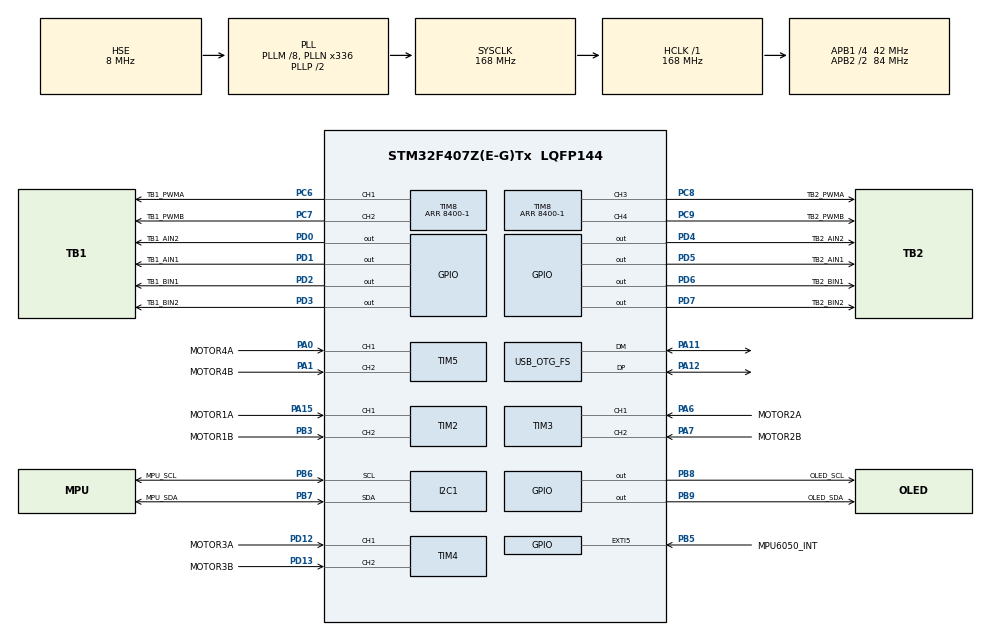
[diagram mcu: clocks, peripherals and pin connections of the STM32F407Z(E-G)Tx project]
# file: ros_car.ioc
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Dma.I2C1_RX.0.Direction=DMA_PERIPH_TO_MEMORY
Dma.I2C1_RX.0.FIFOMode=DMA_FIFOMODE_DISABLE
Dma.I2C1_RX.0.Instance=DMA1_Stream0
Dma.I2C1_RX.0.MemDataAlignment=DMA_MDATAALIGN_BYTE
Dma.I2C1_RX.0.MemInc=DMA_MINC_ENABLE
Dma.I2C1_RX.0.Mode=DMA_NORMAL
Dma.I2C1_RX.0.PeriphDataAlignment=DMA_PDATAALIGN_BYTE
Dma.I2C1_RX.0.PeriphInc=DMA_PINC_DISABLE
Dma.I2C1_RX.0.Priority=DMA_PRIORITY_HIGH
Dma.I2C1_TX.1.Direction=DMA_MEMORY_TO_PERIPH
Dma.I2C1_TX.1.FIFOMode=DMA_FIFOMODE_DISABLE
Dma.I2C1_TX.1.Instance=DMA1_Stream6
Dma.I2C1_TX.1.MemDataAlignment=DMA_MDATAALIGN_BYTE
Dma.I2C1_TX.1.MemInc=DMA_MINC_ENABLE
Dma.I2C1_TX.1.Mode=DMA_NORMAL
Dma.I2C1_TX.1.PeriphDataAlignment=DMA_PDATAALIGN_BYTE
Dma.I2C1_TX.1.PeriphInc=DMA_PINC_DISABLE
Dma.I2C1_TX.1.Priority=DMA_PRIORITY_HIGH
Dma.Request0=I2C1_RX
Dma.Request1=I2C1_TX
FREERTOS.Tasks01=defaultTask,24,128,StartDefaultTask,Default,NULL,Dynamic,NULL,NULL
Mcu.Family=STM32F4
Mcu.Name=STM32F407Z(E-G)Tx
Mcu.Package=LQFP144
NVIC.DMA1_Stream0_IRQn=true\:5\:0\:false\:false\:true\:true\:false\:true\:true
NVIC.DMA1_Stream6_IRQn=true\:5\:0\:false\:false\:true\:true\:false\:true\:true
NVIC.EXTI9_5_IRQn=true\:5\:0\:false\:false\:true\:true\:true\:true\:true
NVIC.I2C1_ER_IRQn=true\:5\:0\:false\:false\:true\:true\:true\:true\:true
NVIC.I2C1_EV_IRQn=true\:5\:0\:false\:false\:true\:true\:true\:true\:true
NVIC.OTG_FS_IRQn=true\:5\:0\:false\:false\:true\:true\:false\:true\:true
NVIC.PriorityGroup=NVIC_PRIORITYGROUP_4
NVIC.TIM1_UP_TIM10_IRQn=true\:15\:0\:false\:false\:true\:false\:false\:true\:true
NVIC.TIM8_TRG_COM_TIM14_IRQn=true\:5\:0\:false\:false\:true\:false\:false\:true\:true
NVIC.TimeBase=TIM1_UP_TIM10_IRQn
NVIC.TimeBaseIP=TIM1
PA0-WKUP.GPIO_Label=MOTOR4A
PA0-WKUP.Signal=S_TIM5_CH1
PA1.GPIO_Label=MOTOR4B
PA1.Signal=S_TIM5_CH2
PA11.Mode=Device_Only
PA11.Signal=USB_OTG_FS_DM
PA12.Mode=Device_Only
PA12.Signal=USB_OTG_FS_DP
PA13.Mode=Serial_Wire
PA13.Signal=SYS_JTMS-SWDIO
PA14.Mode=Serial_Wire
PA14.Signal=SYS_JTCK-SWCLK
PA15.GPIO_Label=MOTOR1A
PA15.Signal=S_TIM2_CH1_ETR
PA6.GPIO_Label=MOTOR2A
PA6.Signal=S_TIM3_CH1
PA7.GPIO_Label=MOTOR2B
PA7.Signal=S_TIM3_CH2
PB3.GPIO_Label=MOTOR1B
PB3.Signal=S_TIM2_CH2
PB5.GPIO_Label=MPU6050_INT
PB5.Signal=GPXTI5
PB6.GPIO_Label=MPU_SCL
PB6.GPIO_Pu=GPIO_PULLUP
PB6.GPIO_Speed=GPIO_SPEED_FREQ_HIGH
PB6.Mode=I2C
PB6.Signal=I2C1_SCL
PB7.GPIO_Label=MPU_SDA
PB7.GPIO_Pu=GPIO_PULLUP
PB7.GPIO_Speed=GPIO_SPEED_FREQ_HIGH
PB7.Mode=I2C
PB7.Signal=I2C1_SDA
PB8.GPIO_Label=OLED_SCL
PB8.GPIO_ModeDefaultOutputPP=GPIO_MODE_OUTPUT_OD
PB8.GPIO_PuPd=GPIO_PULLUP
PB8.GPIO_Speed=GPIO_SPEED_FREQ_HIGH
PB8.Signal=GPIO_Output
PB9.GPIO_Label=OLED_SDA
PB9.GPIO_ModeDefaultOutputPP=GPIO_MODE_OUTPUT_OD
PB9.GPIO_PuPd=GPIO_PULLUP
PB9.GPIO_Speed=GPIO_SPEED_FREQ_HIGH
PB9.Signal=GPIO_Output
PC14-OSC32_IN.Mode=LSE-External-Oscillator
PC14-OSC32_IN.Signal=RCC_OSC32_IN
PC15-OSC32_OUT.Mode=LSE-External-Oscillator
PC15-OSC32_OUT.Signal=RCC_OSC32_OUT
PC6.GPIO_Label=TB1_PWMA
PC6.Signal=S_TIM8_CH1
PC7.GPIO_Label=TB1_PWMB
PC7.Signal=S_TIM8_CH2
PC8.GPIO_Label=TB2_PWMA
PC8.Signal=S_TIM8_CH3
PC9.GPIO_Label=TB2_PWMB
PC9.Signal=S_TIM8_CH4
PD0.GPIO_Label=TB1_AIN2
PD0.GPIO_Speed=GPIO_SPEED_FREQ_LOW
PD0.Signal=GPIO_Output
PD1.GPIO_Label=TB1_AIN1
PD1.GPIO_Speed=GPIO_SPEED_FREQ_LOW
PD1.Signal=GPIO_Output
PD12.GPIO_Label=MOTOR3A
PD12.Signal=S_TIM4_CH1
PD13.GPIO_Label=MOTOR3B
PD13.Signal=S_TIM4_CH2
PD2.GPIO_Label=TB1_BIN1
PD2.GPIO_Speed=GPIO_SPEED_FREQ_LOW
PD2.Signal=GPIO_Output
PD3.GPIO_Label=TB1_BIN2
PD3.GPIO_Speed=GPIO_SPEED_FREQ_LOW
PD3.Signal=GPIO_Output
PD4.GPIO_Label=TB2_AIN2
PD4.GPIO_Speed=GPIO_SPEED_FREQ_LOW
PD4.Signal=GPIO_Output
PD5.GPIO_Label=TB2_AIN1
PD5.GPIO_Speed=GPIO_SPEED_FREQ_LOW
PD5.Signal=GPIO_Output
PD6.GPIO_Label=TB2_BIN1
PD6.GPIO_Speed=GPIO_SPEED_FREQ_LOW
PD6.Signal=GPIO_Output
PD7.GPIO_Label=TB2_BIN2
PD7.GPIO_Speed=GPIO_SPEED_FREQ_LOW
PD7.Signal=GPIO_Output
PH0-OSC_IN.Mode=HSE-External-Oscillator
PH0-OSC_IN.Signal=RCC_OSC_IN
PH1-OSC_OUT.Mode=HSE-External-Oscillator
PH1-OSC_OUT.Signal=RCC_OSC_OUT
ProjectManager.HeapSize=0x3000
ProjectManager.StackSize=0x2000
ProjectManager.TargetToolchain=Makefile
RCC.48MHZClocksFreq_Value=48000000
RCC.AHBFreq_Value=168000000
RCC.APB1CLKDivider=RCC_HCLK_DIV4
RCC.APB1Freq_Value=42000000
RCC.APB1TimFreq_Value=84000000
RCC.APB2CLKDivider=RCC_HCLK_DIV2
RCC.APB2Freq_Value=84000000
RCC.APB2TimFreq_Value=168000000
RCC.CortexFreq_Value=168000000
RCC.HCLKFreq_Value=168000000
RCC.HSE_VALUE=8000000
RCC.HSI_VALUE=16000000
RCC.PLLM=8
RCC.PLLN=336
RCC.PLLQ=7
RCC.SYSCLKFreq_VALUE=168000000
RCC.SYSCLKSource=RCC_SYSCLKSOURCE_PLLCLK
RCC.VCOOutputFreq_Value=336000000
SH.S_TIM2_CH1_ETR.0=TIM2_CH1,Encoder_Interface
SH.S_TIM2_CH2.0=TIM2_CH2,Encoder_Interface
SH.S_TIM3_CH1.0=TIM3_CH1,Encoder_Interface
SH.S_TIM3_CH2.0=TIM3_CH2,Encoder_Interface
SH.S_TIM4_CH1.0=TIM4_CH1,Encoder_Interface
SH.S_TIM4_CH2.0=TIM4_CH2,Encoder_Interface
SH.S_TIM5_CH1.0=TIM5_CH1,Encoder_Interface
SH.S_TIM5_CH2.0=TIM5_CH2,Encoder_Interface
SH.S_TIM8_CH1.0=TIM8_CH1,PWM Generation1 CH1
SH.S_TIM8_CH2.0=TIM8_CH2,PWM Generation2 CH2
SH.S_TIM8_CH3.0=TIM8_CH3,PWM Generation3 CH3
SH.S_TIM8_CH4.0=TIM8_CH4,PWM Generation4 CH4
TIM2.EncoderMode=TIM_ENCODERMODE_TI12
TIM3.EncoderMode=TIM_ENCODERMODE_TI12
TIM4.EncoderMode=TIM_ENCODERMODE_TI12
TIM5.EncoderMode=TIM_ENCODERMODE_TI12
TIM8.Channel-PWM\ Generation1\ CH1=TIM_CHANNEL_1
TIM8.Channel-PWM\ Generation2\ CH2=TIM_CHANNEL_2
TIM8.Channel-PWM\ Generation3\ CH3=TIM_CHANNEL_3
TIM8.Channel-PWM\ Generation4\ CH4=TIM_CHANNEL_4
TIM8.Period=8400-1
USB_DEVICE.CLASS_NAME_FS=CDC
USB_DEVICE.VirtualMode-CDC_FS=Cdc
USB_DEVICE.VirtualModeFS=Cdc_FS
USB_OTG_FS.VirtualMode=Device_Only
VP_FREERTOS_VS_CMSIS_V2.Mode=CMSIS_V2
VP_SYS_VS_tim1.Mode=TIM1
VP_USB_DEVICE_VS_USB_DEVICE_CDC_FS.Mode=CDC_FS
board=custom

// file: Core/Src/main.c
/* USER CODE BEGIN Header */
/**
  ******************************************************************************
  * @file           : main.c
  * @brief          : Main program body
  ******************************************************************************
  * @attention
  *
  * Copyright (c) 2026 STMicroelectronics.
  * All rights reserved.
  *
  * This software is licensed under terms that can be found in the LICENSE file
  * in the root directory of this software component.
  * If no LICENSE file comes with this software, it is provided AS-IS.
  *
  ******************************************************************************
  */
/* USER CODE END Header */
#include "main.h"
#include "cmsis_os.h"
#include "dma.h"
#include "i2c.h"
#include "tim.h"
#include "usb_device.h"
#include "gpio.h"

void SystemClock_Config(void);
void MX_FREERTOS_Init(void);

int main(void)
{

  /* MCU Configuration--------------------------------------------------------*/

  /* Reset of all peripherals, Initializes the Flash interface and the Systick. */
  HAL_Init();

  /* Configure the system clock */
  SystemClock_Config();

  /* Initialize all configured peripherals */
  MX_GPIO_Init();
  MX_DMA_Init();
  MX_I2C1_Init();
  MX_TIM2_Init();
  MX_TIM3_Init();
  MX_TIM4_Init();
  MX_TIM5_Init();
  MX_TIM8_Init();
  /* USER CODE BEGIN 2 */
    ALL_Init();

  /* USER CODE END 2 */

  /* Init scheduler */
  osKernelInitialize();  /* Call init function for freertos objects (in cmsis_os2.c) */
  MX_FREERTOS_Init();

  /* Start scheduler */
  osKernelStart();

  /* We should never get here as control is now taken by the scheduler */

  /* Infinite loop */
    while (1) {

    }
}

void SystemClock_Config(void)
{
  RCC_OscInitTypeDef RCC_OscInitStruct = {0};
  RCC_ClkInitTypeDef RCC_ClkInitStruct = {0};

  /** Configure the main internal regulator output voltage
  */
  __HAL_RCC_PWR_CLK_ENABLE();
  __HAL_PWR_VOLTAGESCALING_CONFIG(PWR_REGULATOR_VOLTAGE_SCALE1);

  /** Initializes the RCC Oscillators according to the specified parameters
  * in the RCC_OscInitTypeDef structure.
  */
  RCC_OscInitStruct.OscillatorType = RCC_OSCILLATORTYPE_HSE;
  RCC_OscInitStruct.HSEState = RCC_HSE_ON;
  RCC_OscInitStruct.PLL.PLLState = RCC_PLL_ON;
  RCC_OscInitStruct.PLL.PLLSource = RCC_PLLSOURCE_HSE;
  RCC_OscInitStruct.PLL.PLLM = 8;
  RCC_OscInitStruct.PLL.PLLN = 336;
  RCC_OscInitStruct.PLL.PLLP = RCC_PLLP_DIV2;
  RCC_OscInitStruct.PLL.PLLQ = 7;
  if (HAL_RCC_OscConfig(&RCC_OscInitStruct) != HAL_OK)
  {
    Error_Handler();
  }

  /** Initializes the CPU, AHB and APB buses clocks
  */
  RCC_ClkInitStruct.ClockType = RCC_CLOCKTYPE_HCLK|RCC_CLOCKTYPE_SYSCLK
                              |RCC_CLOCKTYPE_PCLK1|RCC_CLOCKTYPE_PCLK2;
  RCC_ClkInitStruct.SYSCLKSource = RCC_SYSCLKSOURCE_PLLCLK;
  RCC_ClkInitStruct.AHBCLKDivider = RCC_SYSCLK_DIV1;
  RCC_ClkInitStruct.APB1CLKDivider = RCC_HCLK_DIV4;
  RCC_ClkInitStruct.APB2CLKDivider = RCC_HCLK_DIV2;

  if (HAL_RCC_ClockConfig(&RCC_ClkInitStruct, FLASH_LATENCY_5) != HAL_OK)
  {
    Error_Handler();
  }
}

void HAL_TIM_PeriodElapsedCallback(TIM_HandleTypeDef *htim)
{
  if (htim->Instance == TIM1)
  {
    HAL_IncTick();
  }
}

void Error_Handler(void)
{
    __disable_irq();
    while (1) {
    }
}

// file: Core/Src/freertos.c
/* USER CODE BEGIN Header */
/**
  ******************************************************************************
  * File Name          : freertos.c
  * Description        : Code for freertos applications
  ******************************************************************************
  * @attention
  *
  * Copyright (c) 2026 STMicroelectronics.
  * All rights reserved.
  *
  * This software is licensed under terms that can be found in the LICENSE file
  * in the root directory of this software component.
  * If no LICENSE file comes with this software, it is provided AS-IS.
  *
  ******************************************************************************
  */
/* USER CODE END Header */

#include "FreeRTOS.h"
#include "task.h"
#include "main.h"
#include "cmsis_os.h"

/* USER CODE BEGIN Includes */
#include "task_shared.h"
#include "usb_device.h"
#include "usbd_core.h"
/* USER CODE END Includes */

/* USER CODE BEGIN PTD */
extern USBD_HandleTypeDef hUsbDeviceFS;
/* USER CODE END PTD */

/* Definitions for defaultTask */
osThreadId_t defaultTaskHandle;
const osThreadAttr_t defaultTask_attributes = {
  .name = "defaultTask",
  .stack_size = 128 * 4,
  .priority = (osPriority_t) osPriorityNormal,
};

void StartDefaultTask(void *argument);

extern void MX_USB_DEVICE_Init(void);
void MX_FREERTOS_Init(void); /* (MISRA C 2004 rule 8.1) */

void MX_FREERTOS_Init(void) {

  /* Create the thread(s) */
  /* creation of defaultTask */
  defaultTaskHandle = osThreadNew(StartDefaultTask, NULL, &defaultTask_attributes);

}

void StartDefaultTask(void *argument)
{
  /* init code for USB_DEVICE */
  MX_USB_DEVICE_Init();
  /* USER CODE BEGIN StartDefaultTask */
    START_TaskCreate();
    /* Infinite loop */
    for (;;) {
        osDelay(1);
    }
  /* USER CODE END StartDefaultTask */
}
